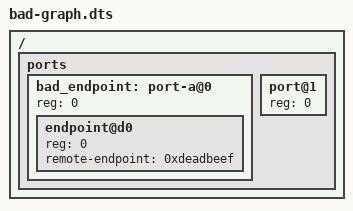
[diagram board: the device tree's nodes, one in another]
/dts-v1/;

/ {
	ports {
		#address-cells = <1>;
		#size-cells = <0>;

		bad_endpoint: port-a@0 {
			reg = <0>;
			#address-cells = <1>;
			#size-cells = <0>;

			endpoint@d0 {
				reg = <0>;
				remote-endpoint = <0xdeadbeef>;
			};

		};

		port@1 {
			reg = <0>;
		};
	};
};
